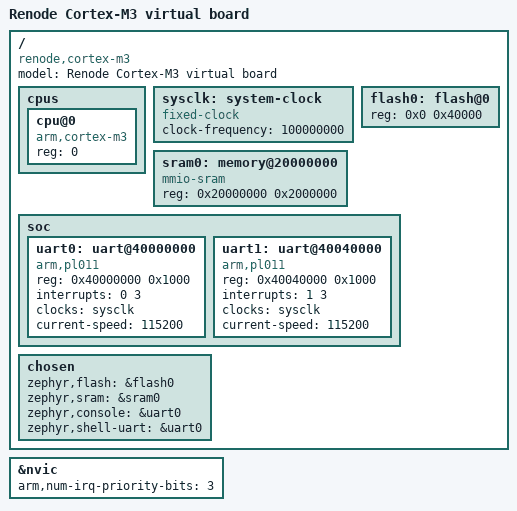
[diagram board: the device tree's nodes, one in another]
/*
 * Renode virtual Cortex-M3 board for the host application.
 *
 * The peripheral map must stay in sync with the Renode machine definition
 * in support/renode_cortex_m3.repl:
 *   ROM   256 KiB @ 0x0
 *   RAM   32 MiB @ 0x20000000
 *   CPU   Cortex-M3 @ 100 MHz (systick)
 *   uart0 console  arm,pl011 @ 0x40000000  IRQ 0
 *   uart1 bus      arm,pl011 @ 0x40040000  IRQ 1
 *
 * Code is linked into the 256 KiB `flash0` region at 0x0 (Renode `rom`);
 * data lives in the 32 MiB SRAM at 0x20000000.
 */

/dts-v1/;

#include <arm/armv7-m.dtsi>

/ {
	#address-cells = <1>;
	#size-cells = <1>;
	compatible = "renode,cortex-m3";
	model = "Renode Cortex-M3 virtual board";

	cpus {
		#address-cells = <1>;
		#size-cells = <0>;
		cpu@0 {
			device_type = "cpu";
			compatible = "arm,cortex-m3";
			reg = <0>;
		};
	};

	sysclk: system-clock {
		compatible = "fixed-clock";
		clock-frequency = <100000000>;
		#clock-cells = <0>;
	};

	/* Code segment: Renode maps a writable 256 KiB region at 0x0
	 * (rom in support/renode_cortex_m3.repl); `loadelf` populates it. */
	flash0: flash@0 {
		reg = <0x0 0x40000>;
	};

	sram0: memory@20000000 {
		compatible = "mmio-sram";
		reg = <0x20000000 0x2000000>;
	};

	soc {
		#address-cells = <1>;
		#size-cells = <1>;
		ranges;

		uart0: uart@40000000 {
			compatible = "arm,pl011";
			reg = <0x40000000 0x1000>;
			interrupts = <0 3>;
			interrupt-names = "uart";
			clocks = <&sysclk>;
		};

		uart1: uart@40040000 {
			compatible = "arm,pl011";
			reg = <0x40040000 0x1000>;
			interrupts = <1 3>;
			interrupt-names = "uart";
			clocks = <&sysclk>;
		};
	};

	chosen {
		zephyr,flash = &flash0;
		zephyr,sram = &sram0;
		zephyr,console = &uart0;
		zephyr,shell-uart = &uart0;
	};
};

&uart0 {
	status = "okay";
	current-speed = <115200>;
};

&uart1 {
	status = "okay";
	current-speed = <115200>;
};

&nvic {
	arm,num-irq-priority-bits = <3>;
};
